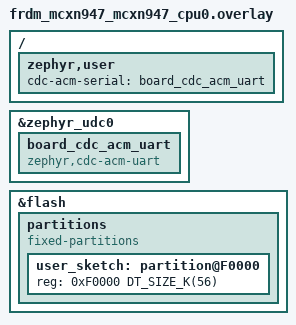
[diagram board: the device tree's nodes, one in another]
/*
 * Copyright (c) Arduino s.r.l. and/or its affiliated companies
 *
 * SPDX-License-Identifier: Apache-2.0
 */

&zephyr_udc0 {
	status = "okay";
	board_cdc_acm_uart: board_cdc_acm_uart {
		compatible = "zephyr,cdc-acm-uart";
		status = "okay";
	};
};

&flash {
	partitions {
		compatible = "fixed-partitions";
		#address-cells = <1>;
		#size-cells = <1>;

		user_sketch: partition@F0000 {
			reg = <0xF0000 DT_SIZE_K(56)>;
		};
	};
};

/ {
	zephyr,user {
		cdc-acm-serial = <&board_cdc_acm_uart>; /* 'Serial' object is managed by SerialUSB */
	};
};
